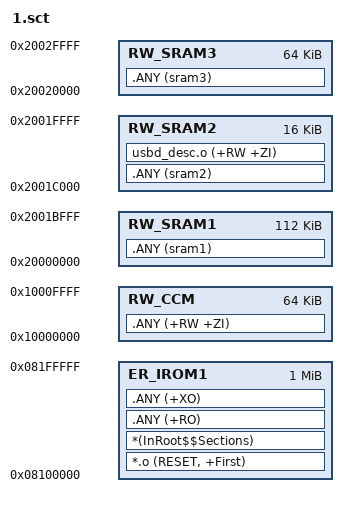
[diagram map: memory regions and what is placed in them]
; *************************************************************
; *** Scatter-Loading Description File generated by uVision ***
; *************************************************************

LR_IROM1 0x08100000 0x00100000  {    ; load region size_region
  ER_IROM1 0x08100000 0x00100000  {  ; load address = execution address
   *.o (RESET, +First)
   *(InRoot$$Sections)
   .ANY (+RO)
   .ANY (+XO)
  }
  RW_SRAM1 0x20000000 0x0001C000  {  ; 112k sram1
   .ANY (sram1)
  }
  RW_SRAM2 0x2001C000 0x00004000  {  ; 16k sram2
   .ANY (sram2)
   usbd_desc.o (+RW +ZI)
  }
  RW_SRAM3 0x20020000 0x00010000  {  ; 64k sram3
   .ANY (sram3)
  }
  RW_CCM   0x10000000 0x00010000  {	 ; 64k ccm
   .ANY (+RW +ZI)
  }
}

